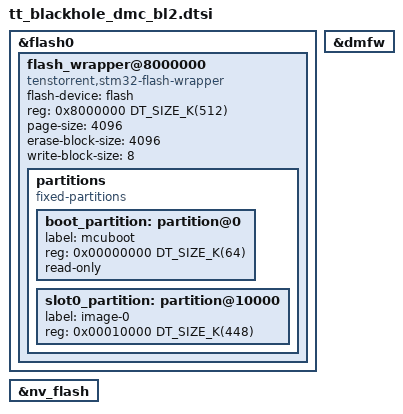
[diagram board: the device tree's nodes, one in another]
/*
 * Copyright (c) 2025 Tenstorrent AI ULC
 *
 * SPDX-License-Identifier: Apache-2.0
 */

/*
 * This overlay defines the partitions used in the new bootloader
 * scheme within the EEPROM, which is shared between the DMC and the SMC
 *
 * It also moves partition around within the DMC DTS to support
 * the new bootloader scheme, since mcuboot updates directly from
 * external flash.
 */

/* Raise the erase block size for the internal flash to 4K */
&flash0 {
	/delete-node/ partitions;
	#address-cells = <1>;
	#size-cells = <1>;
	flash_wrapper@8000000 {
		compatible = "tenstorrent,stm32-flash-wrapper";
		flash-device = <&flash>;
		reg = <0x8000000 DT_SIZE_K(512)>;
		page-size = <4096>;
		erase-block-size = <4096>;
		write-block-size = <8>;

		partitions {
			compatible = "fixed-partitions";
			#address-cells = <1>;
			#size-cells = <1>;

			boot_partition: partition@0 {
				label = "mcuboot";
				reg = <0x00000000 DT_SIZE_K(64)>;
				read-only;
			};

			slot0_partition: partition@10000 {
				label = "image-0";
				reg = <0x00010000 DT_SIZE_K(448)>;
			};
		};
	};
};

&nv_flash {
	/delete-node/ partitions;
	#include "tt_blackhole_fixed_partitions.dtsi"
};

/* Define the DMC firmware partition for MCUBoot */
slot1_partition: &dmfw {};
